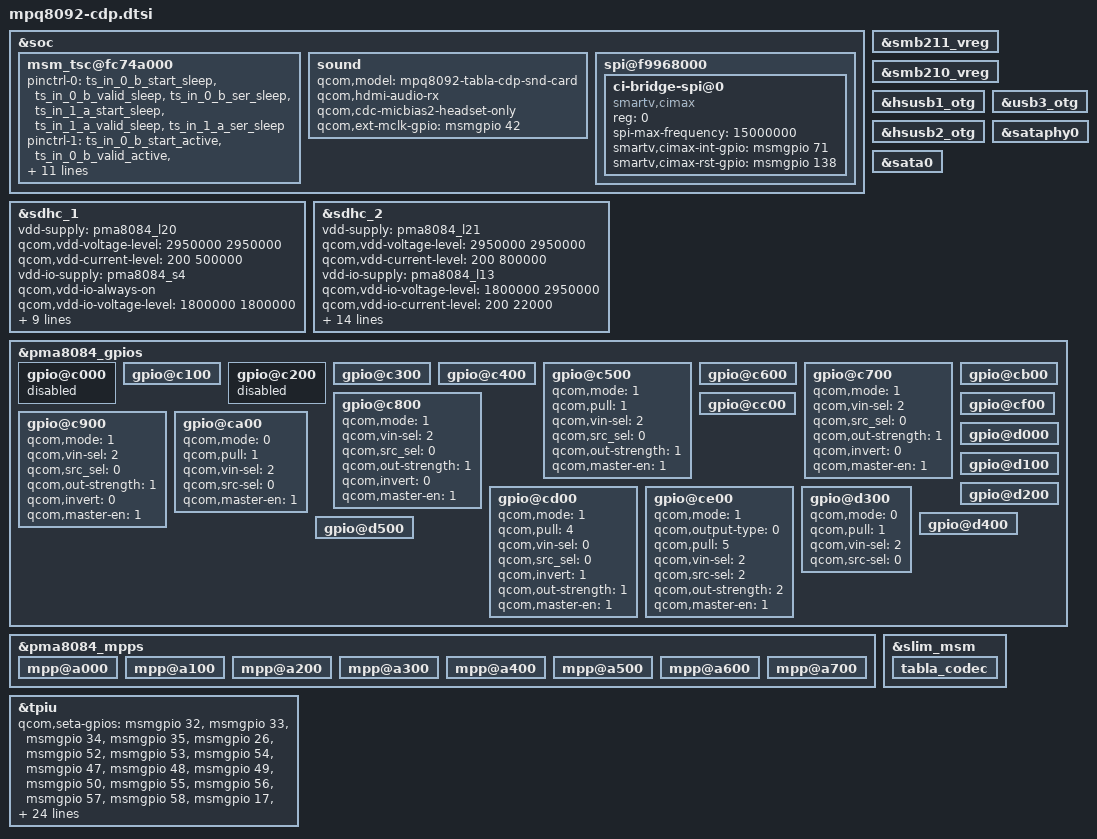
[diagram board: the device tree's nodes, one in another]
/* Copyright (c) 2013-2014, The Linux Foundation. All rights reserved.
 *
 * This program is free software; you can redistribute it and/or modify
 * it under the terms of the GNU General Public License version 2 and
 * only version 2 as published by the Free Software Foundation.
 *
 * This program is distributed in the hope that it will be useful,
 * but WITHOUT ANY WARRANTY; without even the implied warranty of
 * MERCHANTABILITY or FITNESS FOR A PARTICULAR PURPOSE.  See the
 * GNU General Public License for more details.
 */

&soc {
	msm_tsc@fc74a000 {
		pinctrl-names = "disable", "ts-in-0", "ts-in-1", "dual-ts";
		pinctrl-0 = <&ts_in_0_b_start_sleep
					&ts_in_0_b_valid_sleep
					&ts_in_0_b_ser_sleep
					&ts_in_1_a_start_sleep
					&ts_in_1_a_valid_sleep
					&ts_in_1_a_ser_sleep>;	/* disable */
		pinctrl-1 = <&ts_in_0_b_start_active
					&ts_in_0_b_valid_active
					&ts_in_0_b_ser_active
					&ts_in_1_a_start_sleep
					&ts_in_1_a_valid_sleep
					&ts_in_1_a_ser_sleep>; /* ts-in-0 */
		pinctrl-2 = <&ts_in_0_b_start_sleep
					&ts_in_0_b_valid_sleep
					&ts_in_0_b_ser_sleep
					&ts_in_1_a_start_active
					&ts_in_1_a_valid_active
					&ts_in_1_a_ser_active>;	/* ts-in-1 */
		pinctrl-3 = <&ts_in_0_b_start_active
					&ts_in_0_b_valid_active
					&ts_in_0_b_ser_active
					&ts_in_1_a_start_active
					&ts_in_1_a_valid_active
					&ts_in_1_a_ser_active>;	/* dual-ts */
	};
        sound {
                qcom,model = "mpq8092-tabla-cdp-snd-card";
                qcom,hdmi-audio-rx;
                qcom,cdc-micbias2-headset-only;
                qcom,ext-mclk-gpio  = <&msmgpio 42 0>;
        };

	spi@f9968000 {
	   ci-bridge-spi@0 {
			compatible = "smartv,cimax";
			reg = <0>;
			spi-max-frequency = <15000000>;
			smartv,cimax-int-gpio = <&msmgpio 71 0>;
			smartv,cimax-rst-gpio = <&msmgpio 138 0>;
	   };
	};
};

&smb211_vreg {
	status = "ok";
};

&smb210_vreg {
	status = "ok";
};

&hsusb1_otg {
	status = "ok";
};

&hsusb2_otg {
	status = "ok";
};

&usb3_otg {
	status = "ok";
};

&sataphy0 {
	status = "ok";
};

&sata0 {
	status = "ok";
};

&sdhc_1 {
	vdd-supply = <&pma8084_l20>;
	qcom,vdd-voltage-level = <2950000 2950000>;
	qcom,vdd-current-level = <200 500000>;

	vdd-io-supply = <&pma8084_s4>;
	qcom,vdd-io-always-on;
	qcom,vdd-io-voltage-level = <1800000 1800000>;
	qcom,vdd-io-current-level = <200 154000>;

	qcom,pad-pull-on = <0x0 0x3 0x3 0x1>; /* no-pull, pull-up, pull-up, pull-down */
	qcom,pad-pull-off = <0x0 0x3 0x3 0x1>; /* no-pull, pull-up, pull-up, pull-down */
	qcom,pad-drv-on = <0x7 0x4 0x4>; /* 16mA, 10mA, 10mA */
	qcom,pad-drv-off = <0x0 0x0 0x0>; /* 2mA, 2mA, 2mA */

	qcom,clk-rates = <400000 20000000 25000000 50000000 100000000 200000000>;
	qcom,nonremovable;
	qcom,bus-speed-mode = "HS200_1p8v", "DDR_1p8v";
	status = "ok";
 };

&sdhc_2 {
	vdd-supply = <&pma8084_l21>;
	qcom,vdd-voltage-level = <2950000 2950000>;
	qcom,vdd-current-level = <200 800000>;

	vdd-io-supply = <&pma8084_l13>;
	qcom,vdd-io-voltage-level = <1800000 2950000>;
	qcom,vdd-io-current-level = <200 22000>;

	qcom,pad-pull-on = <0x0 0x3 0x3>; /* no-pull, pull-up, pull-up */
	qcom,pad-pull-off = <0x0 0x3 0x3>; /* no-pull, pull-up, pull-up */
	qcom,pad-drv-on = <0x7 0x4 0x4>; /* 16mA, 10mA, 10mA */
	qcom,pad-drv-off = <0x0 0x0 0x0>; /* 2mA, 2mA, 2mA */

	qcom,clk-rates = <400000 20000000 25000000 50000000 100000000 200000000>;
	qcom,bus-speed-mode = "SDR12", "SDR25", "SDR50", "DDR50", "SDR104";

	#address-cells = <0>;
	interrupt-parent = <&sdhc_2>;
	interrupts = <0 1 2>;
	#interrupt-cells = <1>;
	interrupt-map-mask = <0xffffffff>;
	interrupt-map = <0 &intc 0 125 0
			1 &intc 0 221 0
			2 &pma8084_gpios 20 0x3>;
	interrupt-names = "hc_irq", "pwr_irq", "status_irq";
	cd-gpios = <&pma8084_gpios 20 0x1>;

	status = "ok";
};

&pma8084_gpios {
	gpio@c000 { /* GPIO 1 */
		/* SMB210 DBU4 5.0 V regulator enable - no software control */
		status = "disabled";
	};

	gpio@c100 { /* GPIO 2 */
	};

	gpio@c200 { /* GPIO 3 */
		/* SMB211 DBU2 3.3 V regulator enable - no software control */
		status = "disabled";
	};

	gpio@c300 { /* GPIO 4 */
	};

	gpio@c400 { /* GPIO 5 */
	};

	gpio@c500 { /* GPIO 6 */
		qcom,mode = <1>;		/* Digital output */
		qcom,pull = <1>;		/* QPNP_PIN_GPIO_PULL_UP_1P5 */
		qcom,vin-sel = <2>;		/* VIN2 */
		qcom,src_sel = <0>;		/* GPIO */
		qcom,out-strength = <1>;	/* Low */
		qcom,master-en = <1>;		/* Enable GPIO */
	};

	gpio@c600 { /* GPIO 7 */
	};

	gpio@c700 { /* GPIO 8 - USB OTG 3.0 */
		qcom,mode = <1>;	/* Digital output */
		qcom,vin-sel = <2>;	/* PMA8084 S4 = 1.8V */
		qcom,src_sel = <0>;	/* Constant Function */
		qcom,out-strength = <1>;/* Low */
		qcom,invert = <0>;	/* Output low initially */
		qcom,master-en = <1>;	/* Enable GPIO */
	};

	gpio@c800 { /* GPIO 9 -  USB OTG 2.0 (Port-1) */
		qcom,mode = <1>;	/* Digital output */
		qcom,vin-sel = <2>;	/* PMA8084 S4 = 1.8V */
		qcom,src_sel = <0>;	/* Constant Function */
		qcom,out-strength = <1>;/* Low */
		qcom,invert = <0>;	/* Output low initially */
		qcom,master-en = <1>;	/* Enable GPIO */
	};

	gpio@c900 { /* GPIO 10 - USB OTG 2.0 (Port-2) */
		qcom,mode = <1>;	/* Digital output */
		qcom,vin-sel = <2>;	/* PMA8084 S4 = 1.8V */
		qcom,src_sel = <0>;	/* Constant Function */
		qcom,out-strength = <1>;/* Low */
		qcom,invert = <0>;	/* Output low initially */
		qcom,master-en = <1>;	/* Enable GPIO */
	};

	gpio@ca00 { /* GPIO 11 - VBUS interrupt */
		qcom,mode = <0>;	/* Digital input */
		qcom,pull = <1>;	/* 1.5uA pull-up */
		qcom,vin-sel = <2>;	/* PMA8084 S4 = 1.8V */
		qcom,src-sel = <0>;	/* Constant Function */
		qcom,master-en = <1>;	/* Enable GPIO */
	};

	gpio@cb00 { /* GPIO 12 */
	};

	gpio@cc00 { /* GPIO 13 */
	};

	gpio@cd00 { /* GPIO 14 - ETH_RST_N */
		qcom,mode = <1>;         /* Digital output */
		qcom,pull = <4>;         /* PULLDOWN_10UA */
		qcom,vin-sel = <0>;      /* VIN0 */
		qcom,src_sel = <0>;      /* GPIO */
		qcom,invert = <1>;       /* Output high initially */
		qcom,out-strength = <1>; /* Low */
		qcom,master-en = <1>;    /* Enable GPIO */
	};

	gpio@ce00 { /* GPIO 15 */
		qcom,mode = <1>;                /* Digital output */
		qcom,output-type = <0>;         /* CMOS logic */
		qcom,pull = <5>;                /* No pull */
		qcom,vin-sel = <2>;             /* VIN 2 */
		qcom,src-sel = <2>;             /* Function 1 */
		qcom,out-strength = <2>;        /* Medium */
		qcom,master-en = <1>;           /* Enable GPIO */
	};

	gpio@cf00 { /* GPIO 16 */
	};

	gpio@d000 { /* GPIO 17 */
	};

	gpio@d100 { /* GPIO 18 */
	};

	gpio@d200 { /* GPIO 19 */
	};

	gpio@d300 { /* GPIO 20 */
		qcom,mode = <0>;	/* Digitial input */
		qcom,pull = <1>;	/* QPNP_PIN_GPIO_PULL_UP_1P5 */
		qcom,vin-sel = <2>;	/* VIN2 */
		qcom,src-sel = <0>;	/* GPIO */
	};

	gpio@d400 { /* GPIO 21 */
	};

	gpio@d500 { /* GPIO 22 */
	};
};

&pma8084_mpps {
	mpp@a000 { /* MPP 1 */
	};

	mpp@a100 { /* MPP 2 */
	};

	mpp@a200 { /* MPP 3 */
	};

	mpp@a300 { /* MPP 4 */
	};

	mpp@a400 { /* MPP 5 */
	};

	mpp@a500 { /* MPP 6 */
	};

	mpp@a600 { /* MPP 7 */
	};

	mpp@a700 { /* MPP 8 */
	};
};

&slim_msm {
	tabla_codec {
	};
};

/* CoreSight */
&tpiu {
	qcom,seta-gpios = <&msmgpio 32 0>,
			  <&msmgpio 33 0>,
			  <&msmgpio 34 0>,
			  <&msmgpio 35 0>,
			  <&msmgpio 26 0>,
			  <&msmgpio 52 0>,
			  <&msmgpio 53 0>,
			  <&msmgpio 54 0>,
			  <&msmgpio 47 0>,
			  <&msmgpio 48 0>,
			  <&msmgpio 49 0>,
			  <&msmgpio 50 0>,
			  <&msmgpio 55 0>,
			  <&msmgpio 56 0>,
			  <&msmgpio 57 0>,
			  <&msmgpio 58 0>,
			  <&msmgpio 17 0>,
			  <&msmgpio 18 0>;
	qcom,seta-gpios-func = <5 5 5 5 5 4 3 3 8 8 8 8 8 8 8 8 7 6>;
	qcom,seta-gpios-drv =  <7 7 7 7 7 7 7 7 7 7 7 7 7 7 7 7 7 7>;
	qcom,seta-gpios-pull = <0 0 0 0 0 0 0 0 0 0 0 0 0 0 0 0 0 0>;
	qcom,seta-gpios-dir =  <2 2 2 2 2 2 2 2 2 2 2 2 2 2 2 2 2 2>;

	qcom,setb-gpios = <&msmgpio 2 0>,
			  <&msmgpio 8 0>,
			  <&msmgpio 9 0>,
			  <&msmgpio 10 0>,
			  <&msmgpio 19 0>,
			  <&msmgpio 20 0>,
			  <&msmgpio 21 0>,
			  <&msmgpio 22 0>,
			  <&msmgpio 28 0>,
			  <&msmgpio 29 0>,
			  <&msmgpio 30 0>,
			  <&msmgpio 31 0>,
			  <&msmgpio 37 0>,
			  <&msmgpio 38 0>,
			  <&msmgpio 39 0>,
			  <&msmgpio 40 0>,
			  <&msmgpio 51 0>,
			  <&msmgpio 7 0>;
	qcom,setb-gpios-func = <6 8 8 8 4 2 2 2 6 6 6 6 5 4 4 4 7 6>;
	qcom,setb-gpios-drv =  <7 7 7 7 7 7 7 7 7 7 7 7 7 7 7 7 7 7>;
	qcom,setb-gpios-pull = <0 0 0 0 0 0 0 0 0 0 0 0 0 0 0 0 0 0>;
	qcom,setb-gpios-dir =  <2 2 2 2 2 2 2 2 2 2 2 2 2 2 2 2 2 2>;
};
